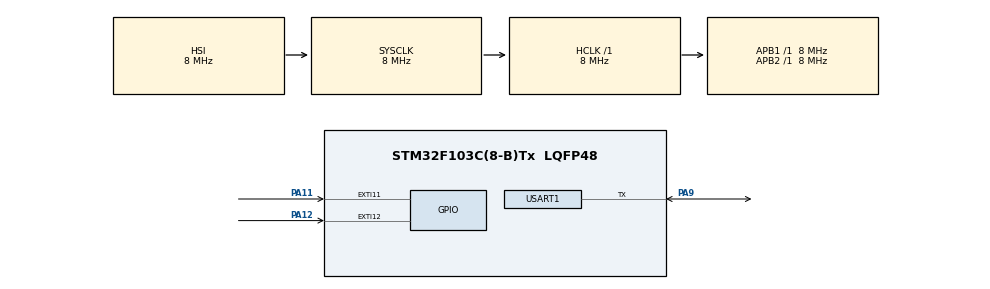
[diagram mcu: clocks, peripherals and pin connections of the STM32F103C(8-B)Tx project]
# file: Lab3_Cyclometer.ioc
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Mcu.Family=STM32F1
Mcu.Name=STM32F103C(8-B)Tx
Mcu.Package=LQFP48
NVIC.EXTI15_10_IRQn=true\:0\:0\:true
NVIC.PVD_IRQn=true\:0\:0\:false
NVIC.PriorityGroup=NVIC_PRIORITYGROUP_4
NVIC.RCC_IRQn=true\:0\:0\:false
NVIC.TIM3_IRQn=true\:0\:0\:false
NVIC.USART1_IRQn=true\:0\:0\:false
PA10.Signal=USART1_RX
PA11.GPIO_ModeDefaultEXTI=GPIO_MODE_IT_FALLING
PA11.GPIO_PuPd=GPIO_PULLUP
PA11.Signal=GPXTI11
PA12.GPIO_ModeDefaultEXTI=GPIO_MODE_IT_FALLING
PA12.GPIO_PuPd=GPIO_PULLUP
PA12.Signal=GPXTI12
PA9.Mode=Half_duplex(single_wire_mode)
PA9.Signal=USART1_TX
ProjectManager.TargetToolchain=MDK-ARM V5
RCC.AHBFreq_Value=8000000
RCC.APB1Freq_Value=8000000
RCC.APB1TimFreq_Value=8000000
RCC.APB2Freq_Value=8000000
RCC.APB2TimFreq_Value=8000000
RCC.HCLKFreq_Value=8000000
RCC.SYSCLKFreq_VALUE=8000000
RCC.USBFreq_Value=8000000
TIM3.Period=999
TIM3.Prescaler=7999
USART1.BaudRate=9600
VP_TIM3_VS_ClockSourceINT.Mode=Internal
board=Lab3_Cyclometer

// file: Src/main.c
/**
  ******************************************************************************
  * File Name          : main.c
  * Description        : Main program body
  ******************************************************************************
  *
  * COPYRIGHT(c) 2019 STMicroelectronics
  *
  * Redistribution and use in source and binary forms, with or without modification,
  * are permitted provided that the following conditions are met:
  *   1. Redistributions of source code must retain the above copyright notice,
  *      this list of conditions and the following disclaimer.
  *   2. Redistributions in binary form must reproduce the above copyright notice,
  *      this list of conditions and the following disclaimer in the documentation
  *      and/or other materials provided with the distribution.
  *   3. Neither the name of STMicroelectronics nor the names of its contributors
  *      may be used to endorse or promote products derived from this software
  *      without specific prior written permission.
  *
  * THIS SOFTWARE IS PROVIDED BY THE COPYRIGHT HOLDERS AND CONTRIBUTORS "AS IS"
  * AND ANY EXPRESS OR IMPLIED WARRANTIES, INCLUDING, BUT NOT LIMITED TO, THE
  * IMPLIED WARRANTIES OF MERCHANTABILITY AND FITNESS FOR A PARTICULAR PURPOSE ARE
  * DISCLAIMED. IN NO EVENT SHALL THE COPYRIGHT HOLDER OR CONTRIBUTORS BE LIABLE
  * FOR ANY DIRECT, INDIRECT, INCIDENTAL, SPECIAL, EXEMPLARY, OR CONSEQUENTIAL
  * DAMAGES (INCLUDING, BUT NOT LIMITED TO, PROCUREMENT OF SUBSTITUTE GOODS OR
  * SERVICES; LOSS OF USE, DATA, OR PROFITS; OR BUSINESS INTERRUPTION) HOWEVER
  * CAUSED AND ON ANY THEORY OF LIABILITY, WHETHER IN CONTRACT, STRICT LIABILITY,
  * OR TORT (INCLUDING NEGLIGENCE OR OTHERWISE) ARISING IN ANY WAY OUT OF THE USE
  * OF THIS SOFTWARE, EVEN IF ADVISED OF THE POSSIBILITY OF SUCH DAMAGE.
  *
  ******************************************************************************
  */
#include "stm32f1xx_hal.h"

/* USER CODE BEGIN Includes */
#include "stdio.h"
/* USER CODE END Includes */

TIM_HandleTypeDef htim3;

UART_HandleTypeDef huart1;

/* USER CODE BEGIN PV */
/* Private variables ---------------------------------------------------------*/
int PA12_Flag = 0; // wheel rolls
int rounds = 0; // assume 2 meters per round
int TIM3_Count = 0; // time in second
int PA11_Flag = 0; // change mode
int mode = 0; // 0 for Mode 1: distance; 1 for Mode 2: speed
/* USER CODE END PV */

void SystemClock_Config(void);
static void MX_GPIO_Init(void);
static void MX_TIM3_Init(void);
static void MX_USART1_UART_Init(void);

/* USER CODE BEGIN PFP */
/* Private function prototypes -----------------------------------------------*/
void HAL_GPIO_EXTI_Callback(uint16_t);
/* USER CODE END PFP */

/* USER CODE BEGIN 0 */
#ifdef __GNUC__
	#define PUTCHAR_PROTOTYPE int __io_putchar(int ch)
#else
	#define PUTCHAR_PROTOTYPE int fputc(int ch, FILE *f)
#endif /* __GNUC_ */
/* USER CODE END 0 */

int main(void)
{

  /* MCU Configuration----------------------------------------------------------*/

  /* Reset of all peripherals, Initializes the Flash interface and the Systick. */
  HAL_Init();

  /* Configure the system clock */
  SystemClock_Config();

  /* Initialize all configured peripherals */
  MX_GPIO_Init();
  MX_TIM3_Init();
  MX_USART1_UART_Init();

  /* USER CODE BEGIN 2 */
	HAL_TIM_Base_Start_IT(&htim3);
  /* USER CODE END 2 */

  /* Infinite loop */
  while (1)
  {

  /* USER CODE BEGIN 3 */
		//printf("Hello, World!\r\n");
		if (PA11_Flag == 1)
		{
			HAL_Delay(10); // anti-jitter
			if (!HAL_GPIO_ReadPin(GPIOA, GPIO_PIN_11))
			{
				mode ^= 1;
				printf("change to Mode %d\r\n", mode+1);
			}
			PA11_Flag = 0;
		}
		if (PA12_Flag == 1)
		{
			HAL_Delay(10); // anti-jitter
			if (!HAL_GPIO_ReadPin(GPIOA, GPIO_PIN_12))
			{
				rounds++;
				if (mode == 0) // distance
				{
					printf("distance: %d m\r\n", rounds*2);
				}
				else
				{
					printf("speed: %f m/s\r\n", rounds*2/(double)TIM3_Count);
				}
			}
			PA12_Flag = 0;
		}
  }
  /* USER CODE END 3 */

}

/** System Clock Configuration
*/
void SystemClock_Config(void)
{

  RCC_OscInitTypeDef RCC_OscInitStruct;
  RCC_ClkInitTypeDef RCC_ClkInitStruct;

  RCC_OscInitStruct.OscillatorType = RCC_OSCILLATORTYPE_HSI;
  RCC_OscInitStruct.HSIState = RCC_HSI_ON;
  RCC_OscInitStruct.HSICalibrationValue = 16;
  RCC_OscInitStruct.PLL.PLLState = RCC_PLL_NONE;
  HAL_RCC_OscConfig(&RCC_OscInitStruct);

  RCC_ClkInitStruct.ClockType = RCC_CLOCKTYPE_SYSCLK;
  RCC_ClkInitStruct.SYSCLKSource = RCC_SYSCLKSOURCE_HSI;
  RCC_ClkInitStruct.AHBCLKDivider = RCC_SYSCLK_DIV1;
  RCC_ClkInitStruct.APB1CLKDivider = RCC_HCLK_DIV1;
  RCC_ClkInitStruct.APB2CLKDivider = RCC_HCLK_DIV1;
  HAL_RCC_ClockConfig(&RCC_ClkInitStruct, FLASH_LATENCY_0);

  HAL_SYSTICK_Config(HAL_RCC_GetHCLKFreq()/1000);

  HAL_SYSTICK_CLKSourceConfig(SYSTICK_CLKSOURCE_HCLK);

}

/* TIM3 init function */
void MX_TIM3_Init(void)
{

  TIM_ClockConfigTypeDef sClockSourceConfig;
  TIM_MasterConfigTypeDef sMasterConfig;

  htim3.Instance = TIM3;
  htim3.Init.Prescaler = 7999;
  htim3.Init.CounterMode = TIM_COUNTERMODE_UP;
  htim3.Init.Period = 999;
  htim3.Init.ClockDivision = TIM_CLOCKDIVISION_DIV1;
  HAL_TIM_Base_Init(&htim3);

  sClockSourceConfig.ClockSource = TIM_CLOCKSOURCE_INTERNAL;
  HAL_TIM_ConfigClockSource(&htim3, &sClockSourceConfig);

  sMasterConfig.MasterOutputTrigger = TIM_TRGO_RESET;
  sMasterConfig.MasterSlaveMode = TIM_MASTERSLAVEMODE_DISABLE;
  HAL_TIMEx_MasterConfigSynchronization(&htim3, &sMasterConfig);

}

/* USART1 init function */
void MX_USART1_UART_Init(void)
{

  huart1.Instance = USART1;
  huart1.Init.BaudRate = 9600;
  huart1.Init.WordLength = UART_WORDLENGTH_8B;
  huart1.Init.StopBits = UART_STOPBITS_1;
  huart1.Init.Parity = UART_PARITY_NONE;
  huart1.Init.Mode = UART_MODE_TX_RX;
  huart1.Init.HwFlowCtl = UART_HWCONTROL_NONE;
  huart1.Init.OverSampling = UART_OVERSAMPLING_16;
  HAL_HalfDuplex_Init(&huart1);

}

/** Configure pins as
        * Analog
        * Input
        * Output
        * EVENT_OUT
        * EXTI
*/
void MX_GPIO_Init(void)
{

  GPIO_InitTypeDef GPIO_InitStruct;

  /* GPIO Ports Clock Enable */
  __GPIOA_CLK_ENABLE();

  /*Configure GPIO pins : PA11 PA12 */
  GPIO_InitStruct.Pin = GPIO_PIN_11|GPIO_PIN_12;
  GPIO_InitStruct.Mode = GPIO_MODE_IT_FALLING;
  GPIO_InitStruct.Pull = GPIO_PULLUP;
  HAL_GPIO_Init(GPIOA, &GPIO_InitStruct);

  /* EXTI interrupt init*/
  HAL_NVIC_SetPriority(EXTI15_10_IRQn, 0, 0);
  HAL_NVIC_EnableIRQ(EXTI15_10_IRQn);

}

/* USER CODE BEGIN 4 */
void HAL_GPIO_EXTI_Callback(uint16_t GPIO_Pin)
{
	if (GPIO_Pin == GPIO_PIN_12)
	{
		PA12_Flag = 1;
	}
	else if (GPIO_Pin == GPIO_PIN_11)
	{
		PA11_Flag = 1;
	}
	else
	{
		UNUSED(GPIO_Pin);
	}
}

void HAL_TIM_PeriodElapsedCallback(TIM_HandleTypeDef *htim)
{
	TIM3_Count++;
}

/**
   * @brief Retargets the C library printf function to the USART
   * @param None
   * @retval None
   */
PUTCHAR_PROTOTYPE
{
	HAL_UART_Transmit(&huart1, (uint8_t*)&ch, 1, 0xffff);
	return ch;
}

/* USER CODE END 4 */

/************************ (C) COPYRIGHT STMicroelectronics *****END OF FILE****/
